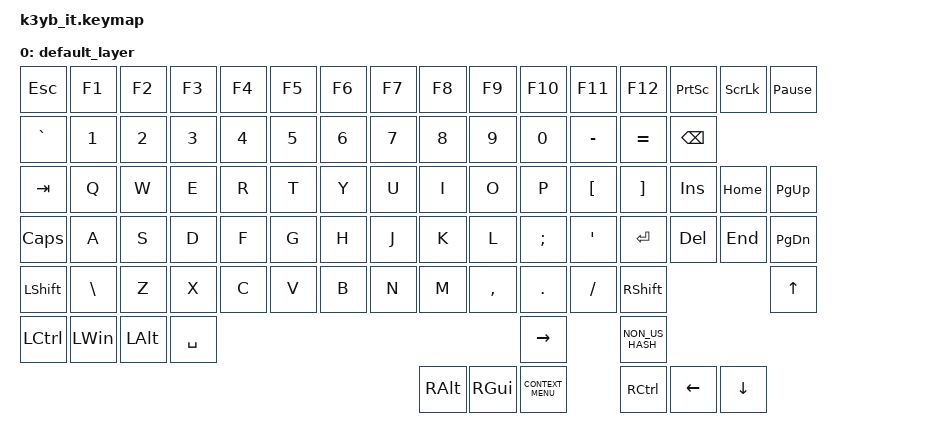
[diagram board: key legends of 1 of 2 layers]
#include <behaviors.dtsi>
#include <dt-bindings/zmk/keys.h>
#include <dt-bindings/zmk/bt.h>

/ {
    keymap {
        compatible = "zmk,keymap";
		
		default_layer {
			//      1   2   3   4   5   6   7   8   9   10  11  12  13  14  15  16
            //    ┌───┬───┬───┬───┬───┬───┬───┬───┬───┬───┬───┬───┬───┬───┬───┬───┐
            //  1 │ESC│ F1│ F2│ F3│ F4│ F5│ F6│ F7│ F8│ F9│F10│F11│F12│PRN│BSC│ PS│
            //    ├───┼───┼───┼───┼───┼───┼───┼───┼───┼───┼───┼───┼───┼───┼───┼───┤
            //  2 │ ` │ 1 │ 2 │ 3 │ 4 │ 5 │ 6 │ 7 │ 8 │ 9 │ 0 │ - │ = │BKS│   │   │
            //    ├───┼───┼───┼───┼───┼───┼───┼───┼───┼───┼───┼───┼───┼───┼───┼───┤
            //  3 │TAB│ q │ w │ e │ r │ t │ y │ u │ i │ o │ p │ [ │ ] │INS│ UP│PGU│
            //    ├───┼───┼───┼───┼───┼───┼───┼───┼───┼───┼───┼───┼───┼───┼───┼───┤
            //  4 │CAP│ a │ s │ d │ f │ g │ h │ j │ k │ l │ ; │ ' │ENT│DEL│END│PGD│
            //    ├───┼───┼───┼───┼───┼───┼───┼───┼───┼───┼───┼───┼───┼───┼───┼───┤
            //  5 │SHL│ \ │ z │ x │ c │ v │ b │ n │ m │ , │ . │ / │SHR│   │   │ UP│
            //    ├───┼───┼───┼───┼───┼───┼───┼───┼───┼───┼───┼───┼───┼───┼───┼───┤
            //  6 │LCT│WIN│LAT│ SP│   │   │   │   │   │   │RIG│   │ # │   │   │   │
            //    ├───┼───┼───┼───┼───┼───┼───┼───┼───┼───┼───┼───┼───┼───┼───┼───┤
            //  7 │   │   │   │   │   │   │   │   │RAL│ FN│MNU│RCT│   │LEF│DOW│   │
            //    └───┴───┴───┴───┴───┴───┴───┴───┴───┴───┴───┴───┴───┴───┴───┴───┘
			bindings = <
			&kp ESC          &kp F1        &kp F2       &kp F3    &kp F4 &kp F5 &kp F6 &kp F7        &kp F8        &kp F9             &kp F10             &kp F11          &kp F12           &kp PRINTSCREEN &kp SCROLLLOCK &kp PAUSE_BREAK
			&kp GRAVE        &kp N1        &kp N2       &kp N3    &kp N4 &kp N5 &kp N6 &kp N7        &kp N8        &kp N9             &kp N0              &kp MINUS        &kp EQUAL         &kp BACKSPACE 
			&kp TAB          &kp Q         &kp W        &kp E     &kp R  &kp T  &kp Y  &kp U         &kp I         &kp O              &kp P               &kp LEFT_BRACKET &kp RIGHT_BRACKET &kp INSERT      &kp HOME       &kp PAGE_UP
			&kp CAPSLOCK     &kp A         &kp S        &kp D     &kp F  &kp G  &kp H  &kp J         &kp K         &kp L              &kp SEMICOLON       &kp SINGLE_QUOTE &kp ENTER         &kp DELETE      &kp END        &kp PAGE_DOWN
			&kp LEFT_SHIFT   &kp BACKSLASH &kp Z        &kp X     &kp C  &kp V  &kp B  &kp N         &kp M         &kp COMMA          &kp DOT             &kp SLASH        &kp RIGHT_SHIFT                                  &kp UP_ARROW
			&kp LEFT_CONTROL &kp LEFT_WIN  &kp LEFT_ALT &kp SPACE                                                                     &kp RIGHT_ARROW                      &kp NON_US_HASH
			                                                                                         &kp RIGHT_ALT &kp RIGHT_GUI      &kp K_CONTEXT_MENU &kp RIGHT_CONTROL                   &kp LEFT_ARROW  &kp DOWN_ARROW
			>;
		};
		
        keypad_layer {
            bindings = <
                //     1   2   3   4
                //   ┌───┬───┬───┬───┐
                // 1 │NUM│ / │ * │ - │
                //   ├───┼───┼───┼───┤
                // 2 │ 7 │ 8 │ 9 │ + │
                //   ├───┼───┼───┼───┤
                // 3 │ 4 │ 5 │ 6 │   │
                //   ├───┼───┼───┼───┤
                // 4 │ 1 │ 2 │ 3 │   │
                //   ├───┼───┼───┼───┤
                // 5 │ 0 │   │ . │RET│
                //   └───┴───┴───┴───┘
                &kp KP_NUMLOCK  &kp KP_DIVIDE   &kp KP_ASTERISK  &kp KP_SUBTRACT
                &kp KP_N7       &kp KP_N8       &kp KP_N9        &kp KP_PLUS
                &kp KP_N4       &kp KP_N5       &kp KP_N6
                &kp KP_N1       &kp KP_N2       &kp KP_N3
                &kp KP_N0                       &kp KP_DOT       &kp KP_ENTER 
            >;
        };
		
    };
  };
